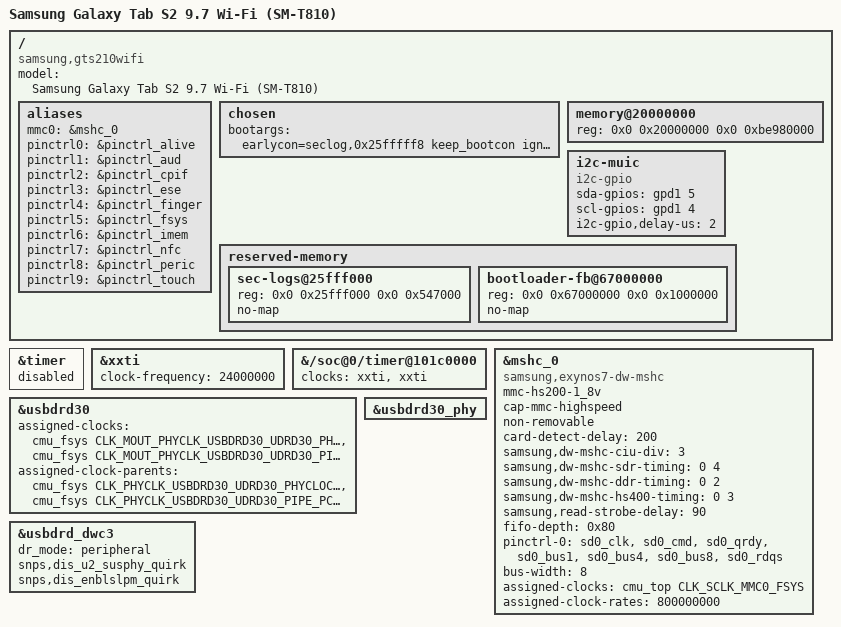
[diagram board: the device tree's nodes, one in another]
// SPDX-License-Identifier: GPL-2.0
/*
 * Samsung Galaxy Tab S2 9.7 Wi-Fi (SM-T810, Exynos 5433) - mainline bring-up.
 *
 * The Samsung bootloader enters the kernel in AArch32 SVC mode with the MMU on,
 * so this is a 32-bit (ARM) kernel using the arm64 SoC description.  One CPU
 * (no PSCI here), logging through the sec_log RAM buffer.
 */
/dts-v1/;
#include <arm64/exynos/exynos5433.dtsi>
#include <dt-bindings/gpio/gpio.h>

/ {
	model = "Samsung Galaxy Tab S2 9.7 Wi-Fi (SM-T810)";
	compatible = "samsung,gts210wifi", "samsung,exynos5433";

	aliases {
		mmc0 = &mshc_0;
		pinctrl0 = &pinctrl_alive;
		pinctrl1 = &pinctrl_aud;
		pinctrl2 = &pinctrl_cpif;
		pinctrl3 = &pinctrl_ese;
		pinctrl4 = &pinctrl_finger;
		pinctrl5 = &pinctrl_fsys;
		pinctrl6 = &pinctrl_imem;
		pinctrl7 = &pinctrl_nfc;
		pinctrl8 = &pinctrl_peric;
		pinctrl9 = &pinctrl_touch;
	};

	chosen {
		bootargs = "earlycon=seclog,0x25fffff8 keep_bootcon ignore_loglevel loglevel=8 printk.time=1 panic=0 clk_ignore_unused rdinit=/init dyndbg=\"file drivers/mmc/core/block.c +p; file drivers/mmc/core/core.c +p; file drivers/mmc/core/mmc.c +p; file drivers/mmc/host/dw_mmc.c +p; file drivers/mmc/host/dw_mmc-exynos.c +p\"";
	};

	/* RAM handed over by S-Boot (ATAGs): 0x20000000-0xde980000 */
	memory@20000000 {
		device_type = "memory";
		reg = <0x0 0x20000000 0x0 0xbe980000>;
	};

	/*
	 * Bit-banged I2C to the SM5703 MUIC (address 0x25).  S-Boot leaves the
	 * connector's D+/D- switched to UART; it must be switched to USB
	 * (MANUAL_SW1 = 0x25) before the USB gadget can be seen by a host.
	 */
	i2c-muic {
		compatible = "i2c-gpio";
		sda-gpios = <&gpd1 5 (GPIO_ACTIVE_HIGH | GPIO_OPEN_DRAIN)>;
		scl-gpios = <&gpd1 4 (GPIO_ACTIVE_HIGH | GPIO_OPEN_DRAIN)>;
		i2c-gpio,delay-us = <2>;
		#address-cells = <1>;
		#size-cells = <0>;
	};

	reserved-memory {
		#address-cells = <2>;
		#size-cells = <2>;
		ranges;

		/* Samsung log areas: sec_log (+header), tima_log, avc_log, pstore */
		sec-logs@25fff000 {
			reg = <0x0 0x25fff000 0x0 0x547000>;
			no-map;
		};

		/* framebuffer set up by S-Boot */
		bootloader-fb@67000000 {
			reg = <0x0 0x67000000 0x0 0x1000000>;
			no-map;
		};
	};
};

/* The ARM generic timer counter is frozen on this device: use the MCT. */
&timer {
	status = "disabled";
};

&xxti {
	clock-frequency = <24000000>;
};

/*
 * The MCT is needed before the CMU drivers probe; give it plain 24 MHz clocks
 * (the PCLK gate is left on by the bootloader; boot with clk_ignore_unused).
 */
&{/soc@0/timer@101c0000} {
	clocks = <&xxti>, <&xxti>;
};

&mshc_0 {
	status = "okay";
	/*
	 * HS200 only (no HS400/DDR): the 8-bit bus test only worked once the
	 * core had switched the pads to 1.8 V for HS200.  Samsung's own DT has
	 * "bypass-smu", so use the non-SMU variant.
	 */
	compatible = "samsung,exynos7-dw-mshc";
	mmc-hs200-1_8v;
	cap-mmc-highspeed;
	non-removable;
	card-detect-delay = <200>;
	samsung,dw-mshc-ciu-div = <3>;
	samsung,dw-mshc-sdr-timing = <0 4>;
	samsung,dw-mshc-ddr-timing = <0 2>;
	samsung,dw-mshc-hs400-timing = <0 3>;
	samsung,read-strobe-delay = <90>;
	fifo-depth = <0x80>;
	pinctrl-names = "default";
	pinctrl-0 = <&sd0_clk &sd0_cmd &sd0_qrdy &sd0_bus1 &sd0_bus4
			&sd0_bus8 &sd0_rdqs>;
	bus-width = <8>;
	assigned-clocks = <&cmu_top CLK_SCLK_MMC0_FSYS>;
	assigned-clock-rates = <800000000>;
};

&usbdrd30 {
	status = "okay";
	/* S-Boot leaves the link clock muxes on OSC; USB only works from the PHY clocks */
	assigned-clocks = <&cmu_fsys CLK_MOUT_PHYCLK_USBDRD30_UDRD30_PHYCLOCK_USER>,
			  <&cmu_fsys CLK_MOUT_PHYCLK_USBDRD30_UDRD30_PIPE_PCLK_USER>;
	assigned-clock-parents = <&cmu_fsys CLK_PHYCLK_USBDRD30_UDRD30_PHYCLOCK_PHY>,
				 <&cmu_fsys CLK_PHYCLK_USBDRD30_UDRD30_PIPE_PCLK_PHY>;
};

&usbdrd_dwc3 {
	dr_mode = "peripheral";
	snps,dis_u2_susphy_quirk;
	snps,dis_enblslpm_quirk;
};

&usbdrd30_phy {
	status = "okay";
};
